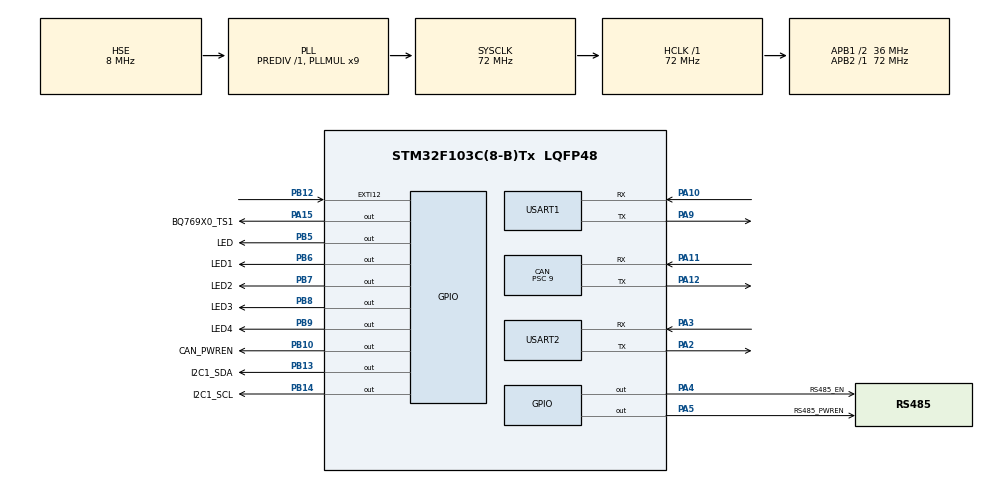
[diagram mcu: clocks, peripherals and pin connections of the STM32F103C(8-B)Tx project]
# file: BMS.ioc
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CAN.ABOM=ENABLE
CAN.AWUM=ENABLE
CAN.BS1=CAN_BS1_7TQ
CAN.BS2=CAN_BS2_8TQ
CAN.CalculateBaudRate=250000
CAN.CalculateTimeBit=4000
CAN.CalculateTimeQuantum=250.0
CAN.Prescaler=9
FREERTOS.Tasks01=defaultTask,24,128,StartDefaultTask,Default,NULL,Dynamic,NULL,NULL
FREERTOS.configTOTAL_HEAP_SIZE=10240
Mcu.Family=STM32F1
Mcu.Name=STM32F103C(8-B)Tx
Mcu.Package=LQFP48
NVIC.CAN1_RX1_IRQn=true\:5\:0\:true\:false\:true\:true\:true\:true\:true
NVIC.EXTI15_10_IRQn=true\:5\:0\:true\:false\:true\:true\:true\:true\:true
NVIC.PriorityGroup=NVIC_PRIORITYGROUP_4
NVIC.TIM4_IRQn=true\:15\:0\:false\:false\:true\:false\:false\:true\:true
NVIC.TimeBase=TIM4_IRQn
NVIC.TimeBaseIP=TIM4
NVIC.USART2_IRQn=true\:5\:0\:true\:false\:true\:true\:true\:true\:true
NVIC.USB_LP_CAN1_RX0_IRQn=true\:5\:0\:false\:false\:true\:true\:true\:true\:true
PA10.Mode=Asynchronous
PA10.Signal=USART1_RX
PA11.Mode=CAN_Activate
PA11.Signal=CAN_RX
PA12.Mode=CAN_Activate
PA12.Signal=CAN_TX
PA13.Mode=Serial_Wire
PA13.Signal=SYS_JTMS-SWDIO
PA14.Mode=Serial_Wire
PA14.Signal=SYS_JTCK-SWCLK
PA15.GPIO_Label=BQ769X0_TS1
PA15.Signal=GPIO_Output
PA2.Mode=Asynchronous
PA2.Signal=USART2_TX
PA3.Mode=Asynchronous
PA3.Signal=USART2_RX
PA4.GPIO_Label=RS485_EN
PA4.PinState=GPIO_PIN_SET
PA4.Signal=GPIO_Output
PA5.GPIO_Label=RS485_PWREN
PA5.GPIO_ModeDefaultOutputPP=GPIO_MODE_OUTPUT_PP
PA5.GPIO_PuPd=GPIO_NOPULL
PA5.PinState=GPIO_PIN_SET
PA5.Signal=GPIO_Output
PA9.Mode=Asynchronous
PA9.Signal=USART1_TX
PB10.GPIO_Label=CAN_PWREN
PB10.GPIO_ModeDefaultOutputPP=GPIO_MODE_OUTPUT_OD
PB10.GPIO_PuPd=GPIO_NOPULL
PB10.PinState=GPIO_PIN_SET
PB10.Signal=GPIO_Output
PB12.GPIO_PuPd=GPIO_NOPULL
PB12.Signal=GPXTI12
PB13.GPIO_Label=I2C1_SDA
PB13.GPIO_Speed=GPIO_SPEED_FREQ_HIGH
PB13.PinState=GPIO_PIN_SET
PB13.Signal=GPIO_Output
PB14.GPIO_Label=I2C1_SCL
PB14.Signal=GPIO_Output
PB5.GPIO_Label=LED
PB5.GPIO_Speed=GPIO_SPEED_FREQ_HIGH
PB5.PinState=GPIO_PIN_SET
PB5.Signal=GPIO_Output
PB6.GPIO_Label=LED1
PB6.GPIO_Speed=GPIO_SPEED_FREQ_HIGH
PB6.PinState=GPIO_PIN_SET
PB6.Signal=GPIO_Output
PB7.GPIO_Label=LED2
PB7.GPIO_Speed=GPIO_SPEED_FREQ_HIGH
PB7.PinState=GPIO_PIN_SET
PB7.Signal=GPIO_Output
PB8.GPIO_Label=LED3
PB8.GPIO_Speed=GPIO_SPEED_FREQ_HIGH
PB8.PinState=GPIO_PIN_SET
PB8.Signal=GPIO_Output
PB9.GPIO_Label=LED4
PB9.GPIO_Speed=GPIO_SPEED_FREQ_HIGH
PB9.PinState=GPIO_PIN_SET
PB9.Signal=GPIO_Output
PD0-OSC_IN.Mode=HSE-External-Oscillator
PD0-OSC_IN.Signal=RCC_OSC_IN
PD1-OSC_OUT.Mode=HSE-External-Oscillator
PD1-OSC_OUT.Signal=RCC_OSC_OUT
ProjectManager.HeapSize=0x400
ProjectManager.StackSize=0x400
ProjectManager.TargetToolchain=MDK-ARM V5
RCC.AHBFreq_Value=72000000
RCC.APB1CLKDivider=RCC_HCLK_DIV2
RCC.APB1Freq_Value=36000000
RCC.APB1TimFreq_Value=72000000
RCC.APB2Freq_Value=72000000
RCC.APB2TimFreq_Value=72000000
RCC.HCLKFreq_Value=72000000
RCC.PLLMUL=RCC_PLL_MUL9
RCC.PLLSourceVirtual=RCC_PLLSOURCE_HSE
RCC.SYSCLKFreq_VALUE=72000000
RCC.SYSCLKSource=RCC_SYSCLKSOURCE_PLLCLK
RCC.USBFreq_Value=72000000
USART1.VirtualMode=VM_ASYNC
USART2.VirtualMode=VM_ASYNC
VP_FREERTOS_VS_CMSIS_V2.Mode=CMSIS_V2
VP_SYS_VS_tim4.Mode=TIM4
board=custom

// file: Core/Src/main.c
/* USER CODE BEGIN Header */
/**
  ******************************************************************************
  * @file           : main.c
  * @brief          : Main program body
  ******************************************************************************
  * @attention
  *
  * Copyright (c) 2022 STMicroelectronics.
  * All rights reserved.
  *
  * This software is licensed under terms that can be found in the LICENSE file
  * in the root directory of this software component.
  * If no LICENSE file comes with this software, it is provided AS-IS.
  *
  ******************************************************************************
  */
/* USER CODE END Header */
#include "main.h"
#include "cmsis_os.h"  /* CMSIS-RTOS鎺ュ彛锛岀敤浜庡垵濮嬪寲鍜屽惎鍔‵reeRTOS銆?*/
#include "can.h"       /* CAN外设句柄和初始化函数声明?*/
#include "usart.h"     /* UART外设句柄和初始化函数声明?*/
#include "gpio.h"      /* GPIO初始化函数声明?*/

/* USER CODE BEGIN Includes */
#include <rtthread.h>  /* 保留的RT-Thread兼容接口；当前主调度器为FreeRTOS?*/

#include "board.h"     /* 鏉跨骇鎺ュ彛澹版槑銆?*/

#include "bms_app.h"   /* BMS鎬诲垵濮嬪寲鎺ュ彛澹版槑銆?*/

/* USER CODE END Includes */

void SystemClock_Config(void);
void MX_FREERTOS_Init(void); /* 创建FreeRTOS对象和默认启动任务?*/

int main(void)
{
  /*
   * 系统启动总入口。执行到osKernelStart()后，CPU控制权交给FreeRTOS
   * 调度器，BMS功能由各个RTOS任务并发运行?
   */

  /* MCU Configuration--------------------------------------------------------*/

  /* Reset of all peripherals, Initializes the Flash interface and the Systick. */
  HAL_Init(); /* 初始化HAL、复位外设并准备系统Tick?*/

  /* Configure the system clock */
  SystemClock_Config(); /* 配置HSE、PLL及HCLK/PCLK时钟树?*/

  /* Initialize all configured peripherals */
  MX_GPIO_Init();         /* 初始化LED、I2C、BQ769x0和控制引脚?*/
  MX_USART1_UART_Init();  /* 初始化调试或通信串口1?*/
  MX_USART2_UART_Init();  /* 初始化通信串口2?*/
  MX_CAN_Init();          /* 初始化CAN外设?*/
  /* USER CODE BEGIN 2 */

  //Board_Initialize();

 // BMS_SysInitialize();

  /* USER CODE END 2 */

  /* Init scheduler */
  osKernelInitialize();  /* 初始化RTOS内核，此时调度器尚未运行?*/
  MX_FREERTOS_Init();     /* 创建默认任务及其他RTOS对象?*/

  /* Start scheduler */
  osKernelStart();        /* 启动调度器，之后由FreeRTOS选择任务运行?*/

  /* We should never get here as control is now taken by the scheduler */
  /* Infinite loop */
  /* USER CODE BEGIN WHILE */
  while (1)
  {
//	HAL_GPIO_TogglePin(LED_GPIO_Port, LED_Pin);
	//rt_kprintf("Hello RT-Thread!\r\n");
//	rt_thread_mdelay(500);

    /* USER CODE END WHILE */

  }
}

void SystemClock_Config(void)
{
  /* RCC振荡器配置结构体：保存HSE、HSI和PLL参数?*/
  RCC_OscInitTypeDef RCC_OscInitStruct = {0};
  /* RCC总线时钟配置结构体：保存SYSCLK、AHB和APB分频参数?*/
  RCC_ClkInitTypeDef RCC_ClkInitStruct = {0};

  /** Initializes the RCC Oscillators according to the specified parameters
  * in the RCC_OscInitTypeDef structure.
  */
  RCC_OscInitStruct.OscillatorType = RCC_OSCILLATORTYPE_HSE;
  RCC_OscInitStruct.HSEState = RCC_HSE_ON;
  RCC_OscInitStruct.HSEPredivValue = RCC_HSE_PREDIV_DIV1;
  RCC_OscInitStruct.HSIState = RCC_HSI_ON;
  RCC_OscInitStruct.PLL.PLLState = RCC_PLL_ON;
  RCC_OscInitStruct.PLL.PLLSource = RCC_PLLSOURCE_HSE;
  RCC_OscInitStruct.PLL.PLLMUL = RCC_PLL_MUL9; /* HSE经PLL进行9倍频?*/
  if (HAL_RCC_OscConfig(&RCC_OscInitStruct) != HAL_OK)
  {
    Error_Handler();
  }

  /** Initializes the CPU, AHB and APB buses clocks
  */
  RCC_ClkInitStruct.ClockType = RCC_CLOCKTYPE_HCLK|RCC_CLOCKTYPE_SYSCLK
                              |RCC_CLOCKTYPE_PCLK1|RCC_CLOCKTYPE_PCLK2;
  RCC_ClkInitStruct.SYSCLKSource = RCC_SYSCLKSOURCE_PLLCLK; /* 系统时钟使用PLL输出。 */
  RCC_ClkInitStruct.AHBCLKDivider = RCC_SYSCLK_DIV1;
  RCC_ClkInitStruct.APB1CLKDivider = RCC_HCLK_DIV2;
  RCC_ClkInitStruct.APB2CLKDivider = RCC_HCLK_DIV1;

  if (HAL_RCC_ClockConfig(&RCC_ClkInitStruct, FLASH_LATENCY_2) != HAL_OK)
  {
    Error_Handler();
  }
}

void HAL_TIM_PeriodElapsedCallback(TIM_HandleTypeDef *htim)
{
  /* htim指向产生周期更新中断的定时器句柄?*/
  if (htim->Instance == TIM4) {
    HAL_IncTick(); /* TIM4作为HAL时间基准，递增uwTick。 */
  }
}

void Error_Handler(void)
{
  /* 初始化失败后关闭中断并停在此处，便于调试器定位故障?*/
  __disable_irq();
  while (1)
  {
  }
}

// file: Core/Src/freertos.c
/*
 * @file freertos.c
 * @brief FreeRTOS入口任务和BMS业务任务启动说明。
 *
 * defaultTask负责调用BMS_SysInitialize()，完成BMS模块初始化；
 * 初始化后继续以500ms周期翻转LED，作为系统运行心跳。
 */
/* USER CODE BEGIN Header */
/**
  ******************************************************************************
  * File Name          : freertos.c
  * Description        : Code for freertos applications
  ******************************************************************************
  * @attention
  *
  * Copyright (c) 2022 STMicroelectronics.
  * All rights reserved.
  *
  * This software is licensed under terms that can be found in the LICENSE file
  * in the root directory of this software component.
  * If no LICENSE file comes with this software, it is provided AS-IS.
  *
  ******************************************************************************
  */
/* USER CODE END Header */

#include "FreeRTOS.h"
#include "task.h"
#include "main.h"
#include "cmsis_os.h"

/* USER CODE BEGIN Includes */
#include "bms_app.h"
/* USER CODE END Includes */

/* Definitions for defaultTask */
osThreadId_t defaultTaskHandle;
const osThreadAttr_t defaultTask_attributes = {
  .name = "defaultTask",
  .stack_size = 128 * 4,
  .priority = (osPriority_t) osPriorityNormal,
};

void StartDefaultTask(void *argument);

void MX_FREERTOS_Init(void); /* (MISRA C 2004 rule 8.1) */

void MX_FREERTOS_Init(void) {
  /* 这里只创建启动任务；BMS 业务任务由 BMS_SysInitialize() 继续创建。 */

  /* 创建启动任务；BMS业务任务将在BMS_SysInitialize()内部创建。 */
  /* creation of defaultTask */
  defaultTaskHandle = osThreadNew(StartDefaultTask, NULL, &defaultTask_attributes);

}

void StartDefaultTask(void *argument)
{
  /* USER CODE BEGIN StartDefaultTask */
  /* Infinite loop */
	(void)argument; /* 当前任务不使用调用方传入的参数。 */
	/* 调度器启动后先完成 I2C、BQ769x0 和各业务模块初始化，再保留本任务作为心跳任务。 */
  BMS_SysInitialize();

  for(;;)
  {
  	HAL_GPIO_TogglePin(LED_GPIO_Port, LED_Pin);
    osDelay(500);
  }
  /* USER CODE END StartDefaultTask */
}
